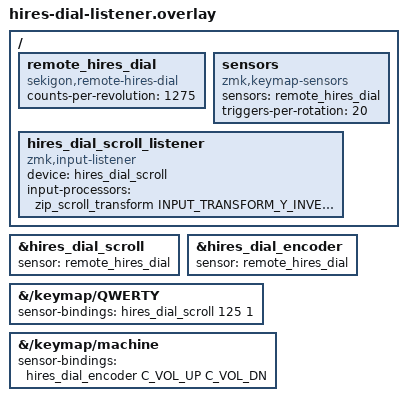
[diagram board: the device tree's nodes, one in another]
#include <behaviors/hires_dial.dtsi>
#include <dt-bindings/zmk/input_transform.h>
#include <dt-bindings/zmk/keys.h>

/ {
    // receives dial events from the peripheral
    remote_hires_dial: remote_hires_dial {
        compatible = "sekigon,remote-hires-dial";
        counts-per-revolution = <1275>;
    };

    sensors {
        compatible = "zmk,keymap-sensors";
        sensors = <&remote_hires_dial>;
        triggers-per-rotation = <20>;
    };

    // scroll behavior reports input events from itself, so it needs a listener
    hires_dial_scroll_listener: hires_dial_scroll_listener {
        compatible = "zmk,input-listener";
        device = <&hires_dial_scroll>;
        input-processors = <&zip_scroll_transform INPUT_TRANSFORM_Y_INVERT>;
    };
};

&hires_dial_scroll {
    sensor = <&remote_hires_dial>;
};

&hires_dial_encoder {
    sensor = <&remote_hires_dial>;
};

// layers without sensor-bindings fall through to QWERTY
&{/keymap/QWERTY} {
    sensor-bindings = <&hires_dial_scroll 125 1>;
};

// holding the dial switches to the machine layer, where rotation adjusts volume
&{/keymap/machine} {
    sensor-bindings = <&hires_dial_encoder C_VOL_UP C_VOL_DN>;
};
